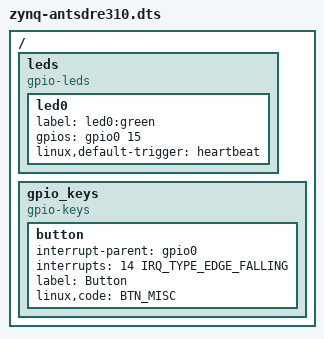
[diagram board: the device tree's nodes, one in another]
// SPDX-License-Identifier: GPL-2.0
/*
 * AD9361-Z7035 System on Module (SOM) SDR - Breakout Carrier
 * Link: https://www.analog.com/ADRV9361-Z7035
 * Link: https://wiki.analog.com/resources/eval/user-guides/adrv936x_rfsom
 *
 * hdl_project: <adrv9361z7035/ccbob_lvds>
 * board_revision: <>
 *
 * Copyright 2015-2019 Analog Devices Inc.
 */
/dts-v1/;
#include "zynq-antsdre310.dtsi"

/ {
	leds {
		compatible = "gpio-leds";
		led0 {
			label = "led0:green";
			gpios = <&gpio0 15 0>;
			linux,default-trigger = "heartbeat";
		};
	};

	gpio_keys {
		compatible = "gpio-keys";
		#address-cells = <1>;
		#size-cells = <0>;

		button {
			interrupt-parent = <&gpio0>;
			interrupts = <14 IRQ_TYPE_EDGE_FALLING>;
			label = "Button";
			linux,code = <BTN_MISC>;
		};

	};
};
